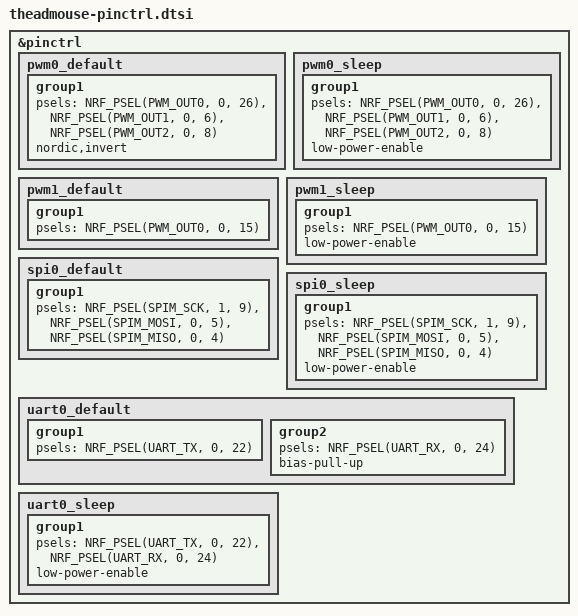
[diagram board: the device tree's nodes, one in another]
/*
 * Copyright (c) 2025 Martin Pietryka
 *
 * SPDX-License-Identifier: Apache-2.0
 */

&pinctrl {
	pwm0_default: pwm0_default {
		group1 {
			psels = <NRF_PSEL(PWM_OUT0, 0, 26)>,	// LED_R
				<NRF_PSEL(PWM_OUT1, 0, 6)>,	// LED_G
				<NRF_PSEL(PWM_OUT2, 0, 8)>;	// LED_B
			nordic,invert;
		};
	};

	pwm0_sleep: pwm0_sleep {
		group1 {
			psels = <NRF_PSEL(PWM_OUT0, 0, 26)>,	// LED_R
				<NRF_PSEL(PWM_OUT1, 0, 6)>,	// LED_G
				<NRF_PSEL(PWM_OUT2, 0, 8)>;	// LED_B
			low-power-enable;
		};
	};

	pwm1_default: pwm1_default {
		group1 {
			psels = <NRF_PSEL(PWM_OUT0, 0, 15)>;	// SPK_PWM
		};
	};

	pwm1_sleep: pwm1_sleep {
		group1 {
			psels = <NRF_PSEL(PWM_OUT0, 0, 15)>;	// SPK_PWM
			low-power-enable;
		};
	};

	spi0_default: spi0_default {
		group1 {
			psels = <NRF_PSEL(SPIM_SCK, 1, 9)>,
				<NRF_PSEL(SPIM_MOSI, 0, 5)>,
				<NRF_PSEL(SPIM_MISO, 0, 4)>;
		};
	};

	spi0_sleep: spi0_sleep {
		group1 {
			psels = <NRF_PSEL(SPIM_SCK, 1, 9)>,
				<NRF_PSEL(SPIM_MOSI, 0, 5)>,
				<NRF_PSEL(SPIM_MISO, 0, 4)>;
			low-power-enable;
		};
	};


	uart0_default: uart0_default {
		group1 {
			psels = <NRF_PSEL(UART_TX, 0, 22)>;
		};
		group2 {
			psels = <NRF_PSEL(UART_RX, 0, 24)>;
			bias-pull-up;
		};
	};

	uart0_sleep: uart0_sleep {
		group1 {
			psels = <NRF_PSEL(UART_TX, 0, 22)>,
				<NRF_PSEL(UART_RX, 0, 24)>;
			low-power-enable;
		};
	};
};
